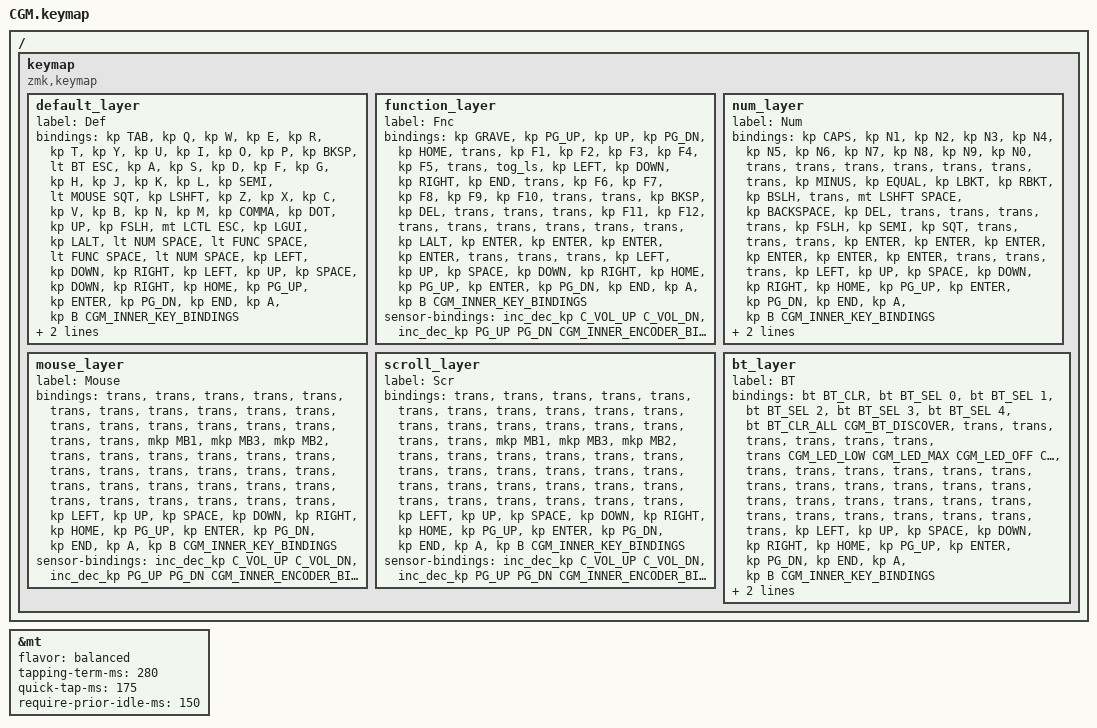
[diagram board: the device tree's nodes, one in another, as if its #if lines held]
// #include <layout_shift.dtsi>

#include <behaviors.dtsi>
#include <dt-bindings/zmk/bt.h>
#include <dt-bindings/zmk/keys.h>
#include <dt-bindings/zmk/pointing.h>
#include <layout_shift_kp_override.dtsi>

#ifndef CGM_LED_LOW
#define CGM_LED_LOW &trans
#define CGM_LED_MAX &trans
#define CGM_LED_OFF &trans
#endif

#ifndef CGM_INNER_KEY_BINDINGS
#define CGM_INNER_KEY_BINDINGS
#endif

#ifndef CGM_INNER_ENCODER_BINDINGS
#define CGM_INNER_ENCODER_BINDINGS
#endif

#define DEF 0
#define FUNC 1
#define NUM 2
#define MOUSE 3
#define SCROLL 4
#define BT 5

&mt {
    flavor = "balanced";
    tapping-term-ms = <280>;
    quick-tap-ms = <175>;
    require-prior-idle-ms = <150>;
};

/ {
    keymap {
        compatible = "zmk,keymap";

        default_layer {
            label = "Def";
            bindings = <
&kp TAB       &kp Q     &kp W      &kp E     &kp R          &kp T               &kp Y           &kp U          &kp I      &kp O      &kp P      &kp BKSP
&lt BT ESC    &kp A     &kp S      &kp D     &kp F          &kp G               &kp H           &kp J          &kp K      &kp L      &kp SEMI   &lt MOUSE SQT
&kp LSHFT     &kp Z     &kp X      &kp C     &kp V          &kp B               &kp N           &kp M          &kp COMMA  &kp DOT    &kp UP     &kp FSLH
&mt LCTL ESC  &kp LGUI  &kp LALT             &lt NUM SPACE  &lt FUNC SPACE      &lt FUNC SPACE  &lt NUM SPACE             &kp LEFT   &kp DOWN   &kp RIGHT
&kp LEFT      &kp UP    &kp SPACE  &kp DOWN  &kp RIGHT                                          &kp HOME       &kp PG_UP  &kp ENTER  &kp PG_DN  &kp END
                                   &kp A                                                                       &kp B CGM_INNER_KEY_BINDINGS
            >;

            sensor-bindings = <&inc_dec_kp C_VOL_UP C_VOL_DN &inc_dec_kp PG_UP PG_DN CGM_INNER_ENCODER_BINDINGS>;
        };

        function_layer {
            label = "Fnc";
            bindings = <
&kp GRAVE  &kp PG_UP  &kp UP     &kp PG_DN  &kp HOME   &trans         &kp F1     &kp F2     &kp F3     &kp F4     &kp F5     &trans
&tog_ls    &kp LEFT   &kp DOWN   &kp RIGHT  &kp END    &trans         &kp F6     &kp F7     &kp F8     &kp F9     &kp F10    &trans
&trans     &kp BKSP   &kp DEL    &trans     &trans     &trans         &kp F11    &kp F12    &trans     &trans     &trans     &trans
&trans     &trans     &kp LALT              &kp ENTER  &kp ENTER      &kp ENTER  &kp ENTER             &trans     &trans     &trans
&kp LEFT   &kp UP     &kp SPACE  &kp DOWN   &kp RIGHT                            &kp HOME   &kp PG_UP  &kp ENTER  &kp PG_DN  &kp END
                                 &kp A                                                      &kp B CGM_INNER_KEY_BINDINGS
            >;

            sensor-bindings = <&inc_dec_kp C_VOL_UP C_VOL_DN &inc_dec_kp PG_UP PG_DN CGM_INNER_ENCODER_BINDINGS>;
        };

        num_layer {
            label = "Num";
            bindings = <
&kp CAPS         &kp N1         &kp N2     &kp N3    &kp N4     &kp N5         &kp N6     &kp N7     &kp N8     &kp N9     &kp N0     &trans
&trans           &trans         &trans     &trans    &trans     &trans         &kp MINUS  &kp EQUAL  &kp LBKT   &kp RBKT   &kp BSLH   &trans
&mt LSHFT SPACE  &kp BACKSPACE  &kp DEL    &trans    &trans     &trans         &trans     &kp FSLH   &kp SEMI   &kp SQT    &trans     &trans
&trans           &kp ENTER      &kp ENTER            &kp ENTER  &kp ENTER      &kp ENTER  &kp ENTER             &trans     &trans     &trans
&kp LEFT         &kp UP         &kp SPACE  &kp DOWN  &kp RIGHT                            &kp HOME   &kp PG_UP  &kp ENTER  &kp PG_DN  &kp END
                                           &kp A                                                     &kp B CGM_INNER_KEY_BINDINGS
            >;

            sensor-bindings = <&inc_dec_kp C_VOL_UP C_VOL_DN &inc_dec_kp PG_UP PG_DN CGM_INNER_ENCODER_BINDINGS>;
        };

        mouse_layer {
            label = "Mouse";
            bindings = <
&trans    &trans  &trans     &trans    &trans     &trans      &trans  &trans    &trans     &trans     &trans     &trans
&trans    &trans  &trans     &trans    &trans     &trans      &trans  &mkp MB1   &mkp MB3   &mkp MB2  &trans     &trans
&trans    &trans  &trans     &trans    &trans     &trans      &trans  &trans    &trans     &trans     &trans     &trans
&trans    &trans  &trans               &trans     &trans      &trans  &trans               &trans     &trans     &trans
&kp LEFT  &kp UP  &kp SPACE  &kp DOWN  &kp RIGHT                      &kp HOME  &kp PG_UP  &kp ENTER  &kp PG_DN  &kp END
                             &kp A                                              &kp B CGM_INNER_KEY_BINDINGS
            >;

            sensor-bindings = <&inc_dec_kp C_VOL_UP C_VOL_DN &inc_dec_kp PG_UP PG_DN CGM_INNER_ENCODER_BINDINGS>;
        };

        scroll_layer {
            label = "Scr";
            bindings = <
&trans    &trans  &trans     &trans    &trans     &trans      &trans  &trans    &trans     &trans     &trans     &trans
&trans    &trans  &trans     &trans    &trans     &trans      &trans  &mkp MB1   &mkp MB3   &mkp MB2  &trans     &trans
&trans    &trans  &trans     &trans    &trans     &trans      &trans  &trans    &trans     &trans     &trans     &trans
&trans    &trans  &trans               &trans     &trans      &trans  &trans               &trans     &trans     &trans
&kp LEFT  &kp UP  &kp SPACE  &kp DOWN  &kp RIGHT                      &kp HOME  &kp PG_UP  &kp ENTER  &kp PG_DN  &kp END
                             &kp A                                              &kp B CGM_INNER_KEY_BINDINGS
            >;

            sensor-bindings = <&inc_dec_kp C_VOL_UP C_VOL_DN &inc_dec_kp PG_UP PG_DN CGM_INNER_ENCODER_BINDINGS>;
        };

#ifdef CAGIME_STUDIO_BLE
#define CGM_BT_DISCOVER &studio_unlock
#else
#define CGM_BT_DISCOVER &trans
#endif
        bt_layer {
            label = "BT";
            bindings = <
&bt BT_CLR  &bt BT_SEL 0  &bt BT_SEL 1  &bt BT_SEL 2  &bt BT_SEL 3  &bt BT_SEL 4      &bt BT_CLR_ALL  CGM_BT_DISCOVER    &trans     &trans     &trans     &trans
&trans      &trans        &trans        CGM_LED_LOW   CGM_LED_MAX      CGM_LED_OFF     CGM_LED_OFF CGM_LED_MAX CGM_LED_LOW &trans     &trans     &trans
&trans      &trans        &trans        &trans        &trans        &trans            &trans          &trans    &trans     &trans     &trans     &trans
&trans      &trans        &trans                      &trans        &trans            &trans          &trans               &trans     &trans     &trans
&kp LEFT    &kp UP        &kp SPACE     &kp DOWN      &kp RIGHT                                       &kp HOME  &kp PG_UP  &kp ENTER  &kp PG_DN  &kp END
                                        &kp A                                                                   &kp B CGM_INNER_KEY_BINDINGS
            >;

            sensor-bindings = <&inc_dec_kp C_VOL_UP C_VOL_DN &inc_dec_kp PG_UP PG_DN CGM_INNER_ENCODER_BINDINGS>;
        };
    };
};
